# A64 register map
Vendor: Allwinner; Series: A64; File version: 0.1
CPU: CA53 0, little endian, MPU, no FPU, 0 interrupt priority bits
Registers are 32-bit, read-write, reset 0x0 unless marked. A register's access mark holds for its fields unless they carry their own. Offsets are from the block's base; [hi:lo] are bit positions; {n}, {i} and the like mark numbered series.

## Thermal_Sensor
Base 0x01C25000
0x00 THS_CTRL_REG0
  [15:0] SENSOR_ACQ0 — ADC acquire time CLK_IN/(N+1)
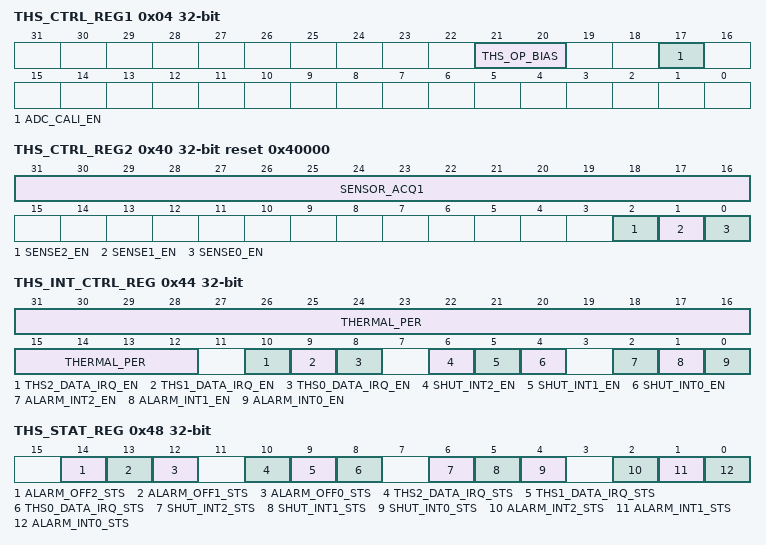
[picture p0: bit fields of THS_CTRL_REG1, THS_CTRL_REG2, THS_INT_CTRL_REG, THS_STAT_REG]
0x04 THS_CTRL_REG1
  [21:20] THS_OP_BIAS
  [17] ADC_CALI_EN — ADC Calibration 1: start Calibration, it is clear to 0 after calibration
    1=start Calibration, it is clear to 0 after calibration
0x14 ADC_CDAT_REG reset not defined
  [11:0] ADC_CDAT — ADC calibration data
0x40 THS_CTRL_REG2 reset 0x40000
  [31:16] SENSOR_ACQ1 — Sensor acquire time CLK_IN/(N+1)
  [2] SENSE2_EN — Enable temperature measurement sensor2 0:Disable 1:Enable
  [1] SENSE1_EN — Enable temperature measurement sensor1 0:Disable 1:Enable
  [0] SENSE0_EN — Enable temperature measurement sensor0 0:Disable 1:Enable
0x44 THS_INT_CTRL_REG
  [31:12] THERMAL_PER — 4096*(n+1)/CLK_IN
  [10] THS2_DATA_IRQ_EN — Selects Temperature measurement data of sensor2 0: No select 1: Select
    0=No_select; 1=Select
  [9] THS1_DATA_IRQ_EN — Selects Temperature measurement data of sensor1 0: No select 1: Select
    0=No_select; 1=Select
  [8] THS0_DATA_IRQ_EN — Selects Temperature measurement data of sensor0 0: No select 1: Select
    0=No_select; 1=Select
  [6] SHUT_INT2_EN — Selects shutdown interrupt for sensor2 0: No select 1: Select
    0=No_select; 1=Select
  [5] SHUT_INT1_EN — Selects shutdown interrupt for sensor1 0: No select 1: Select
    0=No_select; 1=Select
  [4] SHUT_INT0_EN — Selects shutdown interrupt for sensor0 0: No select 1: Select
    0=No_select; 1=Select
  [2] ALARM_INT2_EN — Selects Alert interrupt for sensor2 0: No select 1: Select
    0=No_select; 1=Select
  [1] ALARM_INT1_EN — Selects Alert interrupt for sensor1 0: No select 1: Select
    0=No_select; 1=Select
  [0] ALARM_INT0_EN — Selects Alert interrupt for sensor0 0: No select 1: Select
    0=No_select; 1=Select
0x48 THS_STAT_REG
  [14] ALARM_OFF2_STS — Alarm interrupt off pending for sensor2 Write `1` to clear this interrupt or automatic clear if interrupt condition fails
  [13] ALARM_OFF1_STS — Alarm interrupt off pending for sensor1 Write `1` to clear this interrupt or automatic clear if interrupt condition fails
  [12] ALARM_OFF0_STS — Alarm interrupt off pending for sensor0 Write `1` to clear this interrupt or automatic clear if interrupt condition fails
  [10] THS2_DATA_IRQ_STS — Data interrupt status for sensor2 Write `1` to clear this interrupt or automatic clear if interrupt condition fails
  [9] THS1_DATA_IRQ_STS — Data interrupt status for sensor1 Write `1` to clear this interrupt or automatic clear if interrupt condition fails
  [8] THS0_DATA_IRQ_STS — Data interrupt status for sensor0 Write `1` to clear this interrupt or automatic clear if interrupt condition fails
  [6] SHUT_INT2_STS — Shutdown interrupt status for sensor2 Write `1` to clear this interrupt or automatic clear if interrupt condition fails
  [5] SHUT_INT1_STS — Shutdown interrupt status for sensor1 Write `1` to clear this interrupt or automatic clear if interrupt condition fails
  [4] SHUT_INT0_STS — Shutdown interrupt status for sensor0 Write `1` to clear this interrupt or automatic clear if interrupt condition fails
  [2] ALARM_INT2_STS — Alarm interrupt pending for sensor2 Write `1` to clear this interrupt or automatic clear if interrupt condition fails
  [1] ALARM_INT1_STS — Alarm interrupt pending for sensor1 Write `1` to clear this interrupt or automatic clear if interrupt condition fails
  [0] ALARM_INT0_STS — Alarm interrupt pending for sensor0 Write `1` to clear this interrupt or automatic clear if interrupt condition fails
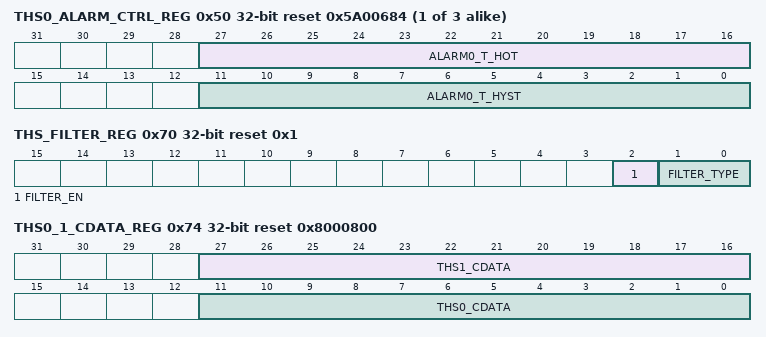
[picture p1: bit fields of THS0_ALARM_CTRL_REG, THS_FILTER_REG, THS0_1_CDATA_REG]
{0x50+4i} THS{i}_ALARM_CTRL_REG reset 0x5A00684 (i=0..2)
  [27:16] ALARM{i}_T_HOT — Thermal sensor{i} Alarm Threshold for hot temperature
  [11:0] ALARM{i}_T_HYST — Thermal sensor{i} Alarm threshold for hysteresis temperature
{0x60+4i} THS{i}_SHUTDOWN_CTRL_REG reset 0x4E90000 (i=0..2)
  [27:16] SHUT{i}_T_HOT — Thermal sensor{i} Shutdown Threshold for hot temperature
0x70 THS_FILTER_REG reset 0x1
  [2] FILTER_EN — Filter Enable 0: Disable 1: Enable
    0=Disable; 1=Enable
  [1:0] FILTER_TYPE — Average Filter Type 00: 2 01: 4 10: 8 11: 16
    0=_2; 1=_4; 2=_8; 3=_16
0x74 THS0_1_CDATA_REG reset 0x8000800
  [27:16] THS1_CDATA — Thermal Sensor1 calibration data
  [11:0] THS0_CDATA — Thermal Sensor0 calibration data
0x78 THS2_CDATA_REG reset 0x800
  [11:0] THS2_CDATA — Thermal Sensor2 calibration data
{0x80+4i} THS{i}_DATA_REG (i=0..2)
  [11:0] THS{i}_DATA ro — Temperature measurement data of sensor{i}
